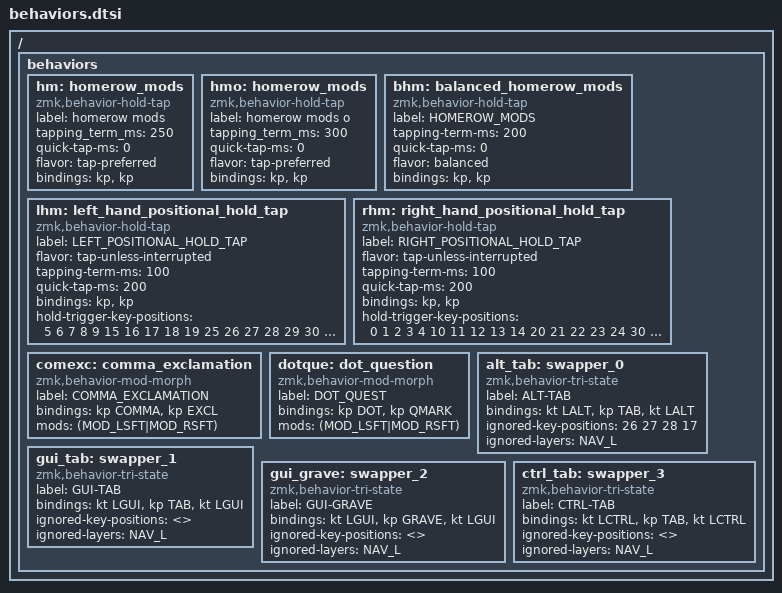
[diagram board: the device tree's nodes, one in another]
/ {
    behaviors {
        hm: homerow_mods {
            compatible = "zmk,behavior-hold-tap";
            label = "homerow mods";
            #binding-cells = <2>;
            tapping_term_ms = <250>;
            quick-tap-ms = <0>;
            flavor = "tap-preferred";
            bindings = <&kp>, <&kp>;
        };
        hmo: homerow_mods {
            compatible = "zmk,behavior-hold-tap";
            label = "homerow mods o";
            #binding-cells = <2>;
            tapping_term_ms = <300>;
            quick-tap-ms = <0>;
            flavor = "tap-preferred";
            bindings = <&kp>, <&kp>;
        };
        bhm: balanced_homerow_mods {
            compatible = "zmk,behavior-hold-tap";
            label = "HOMEROW_MODS";
            #binding-cells = <2>;
            tapping-term-ms = <200>;    // <---[[moderate duration]]
            quick-tap-ms = <0>;
            flavor = "balanced";
            bindings = <&kp>, <&kp>;
        };

        lhm: left_hand_positional_hold_tap {
            compatible = "zmk,behavior-hold-tap";
            label = "LEFT_POSITIONAL_HOLD_TAP";
            #binding-cells = <2>;
            flavor = "tap-unless-interrupted";
            tapping-term-ms = <100>;                        // <---[[produces tap if held longer than tapping-term-ms]]
            quick-tap-ms = <200>;
            bindings = <&kp>, <&kp>;
            hold-trigger-key-positions = <5 6 7 8 9 15 16 17 18 19 25 26 27 28 29 30 31 32 33>;    // <---[[right-hand keys]]
        };

        rhm: right_hand_positional_hold_tap {
            compatible = "zmk,behavior-hold-tap";
            label = "RIGHT_POSITIONAL_HOLD_TAP";
            #binding-cells = <2>;
            flavor = "tap-unless-interrupted";
            tapping-term-ms = <100>;                        // <---[[produces tap if held longer than tapping-term-ms]]
            quick-tap-ms = <200>;
            bindings = <&kp>, <&kp>;
            hold-trigger-key-positions = <0 1 2 3 4 10 11 12 13 14 20 21 22 23 24 30 31 32 33>;    // <---[[left-hand keys]]
        };

        comexc: comma_exclamation {
            compatible = "zmk,behavior-mod-morph";
            label = "COMMA_EXCLAMATION";
            #binding-cells = <0>;
            bindings = <&kp COMMA>, <&kp EXCL>;
            mods = <(MOD_LSFT|MOD_RSFT)>;
        };

        dotque: dot_question {
            compatible = "zmk,behavior-mod-morph";
            label = "DOT_QUEST";
            #binding-cells = <0>;
            bindings = <&kp DOT>, <&kp QMARK>;
            mods = <(MOD_LSFT|MOD_RSFT)>;
        };

        alt_tab: swapper_0 {
            compatible = "zmk,behavior-tri-state";
            label = "ALT-TAB";
            #binding-cells = <0>;
            bindings = <&kt LALT>, <&kp TAB>, <&kt LALT>;
            ignored-key-positions = <26 27 28 17>;
            ignored-layers = <NAV_L>;
        };

        gui_tab: swapper_1 {
            compatible = "zmk,behavior-tri-state";
            label = "GUI-TAB";
            #binding-cells = <0>;
            bindings = <&kt LGUI>, <&kp TAB>, <&kt LGUI>;
            ignored-key-positions = <>;
            ignored-layers = <NAV_L>;
        };

        gui_grave: swapper_2 {
            compatible = "zmk,behavior-tri-state";
            label = "GUI-GRAVE";
            #binding-cells = <0>;
            bindings = <&kt LGUI>, <&kp GRAVE>, <&kt LGUI>;
            ignored-key-positions = <>;
            ignored-layers = <NAV_L>;
        };
        
        ctrl_tab: swapper_3 {
            compatible = "zmk,behavior-tri-state";
            label = "CTRL-TAB";
            #binding-cells = <0>;
            bindings = <&kt LCTRL>, <&kp  TAB>, <&kt LCTRL>;
            ignored-key-positions = <>;
            ignored-layers = <NAV_L>;
        };
    };
};
